# S6E2G3xH register map
Vendor: Spansion; File version: 2.0
CPU: CM4 r0p1, little endian, MPU, FPU, 4 interrupt priority bits
Registers are 32-bit, read-write, reset 0x0 unless marked. A register's access mark holds for its fields unless they carry their own. Offsets are from the block's base; [hi:lo] are bit positions; {n}, {i} and the like mark numbered series.

## USB0 — USB0 Function
Base 0x40042100
Same registers: USB1 0x40052100
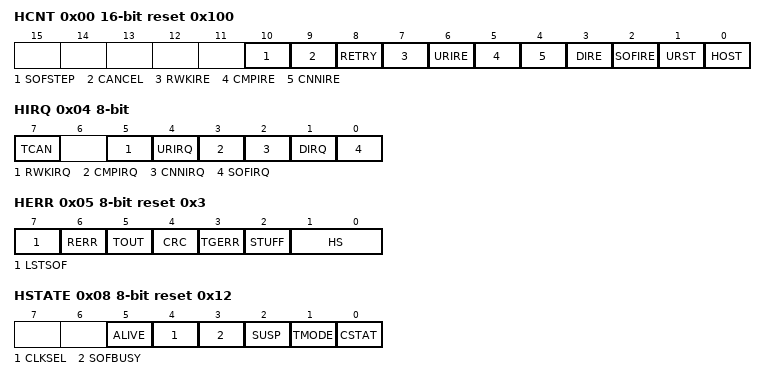
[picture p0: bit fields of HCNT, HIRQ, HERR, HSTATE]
0x00 HCNT 16-bit reset 0x100 — Host Control Register
  [10] SOFSTEP — SOF interrupt occurrence selection bit
  [9] CANCEL — token cancellation enable bit
  [8] RETRY — retry enable bit
  [7] RWKIRE — resume interrupt enable bit
  [6] URIRE — bus reset interrupt enable bit
  [5] CMPIRE — token completion interrupt enable bit
  [4] CNNIRE — device connection detection interrupt enable bit
  [3] DIRE — device disconnection detection interrupt enable bit
  [2] SOFIRE — SOF interrupt enable bit
  [1] URST — bus reset bit
  [0] HOST — host mode bit
0x04 HIRQ 8-bit — Host Interrupt Register
  [7] TCAN — token cancellation flag
  [5] RWKIRQ — remote Wake-up end flag
  [4] URIRQ — bus reset end flag
  [3] CMPIRQ — token completion flag
  [2] CNNIRQ — device connection detection flag
  [1] DIRQ — device disconnection detection flag
  [0] SOFIRQ — SOF starting flag
0x05 HERR 8-bit reset 0x3 — Host Error Status Register
  [7] LSTSOF — lost SOF flag
  [6] RERR — receive error flag
  [5] TOUT — timeout flag
  [4] CRC — CRC error flag
  [3] TGERR — toggle error flag
  [2] STUFF — stuffing error flag
  [1:0] HS — handshake status flags
0x08 HSTATE 8-bit reset 0x12 — Host Status Register
  [5] ALIVE — specify the keep-alive function in the low-speed mode
  [4] CLKSEL — USB operation clock selection bit
  [3] SOFBUSY — SOF busy flag
  [2] SUSP — suspend setting bit
  [1] TMODE ro — transmission mode flag
  [0] CSTAT ro — connection status flag
0x09 HFCOMP 8-bit — SOF Interrupt Frame Compare Register
  [7:0] FRAMECOMP — frame compare data
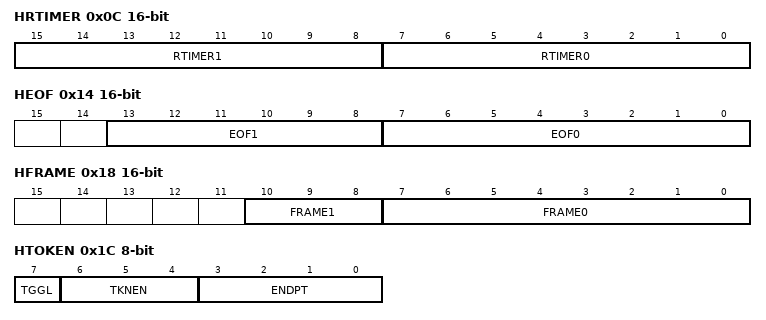
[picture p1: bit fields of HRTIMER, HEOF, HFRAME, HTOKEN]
0x0C HRTIMER 16-bit — Retry Timer Setup Register
  [15:8] RTIMER1 — retry timer setting 1
  [7:0] RTIMER0 — retry timer setting 0
0x10 HRTIMER2 8-bit — Retry Timer Setup Register 2
  [1:0] RTIMER2 — retry timer setting 2
0x11 HADR 8-bit — Host Address Register
  [6:0] ADDRESS — Host Address
0x14 HEOF 16-bit — EOF Setup Register
  [13:8] EOF1 — End Frame 1
  [7:0] EOF0 — End Frame 0
0x18 HFRAME 16-bit — Frame Setup Register
  [10:8] FRAME1 — Frame Setup 1
  [7:0] FRAME0 — Frame Setup 0
0x1C HTOKEN 8-bit — Host Token Endpoint Register
  [7] TGGL — toggle bit
  [6:4] TKNEN — token enable bits
  [3:0] ENDPT — endpoint bits
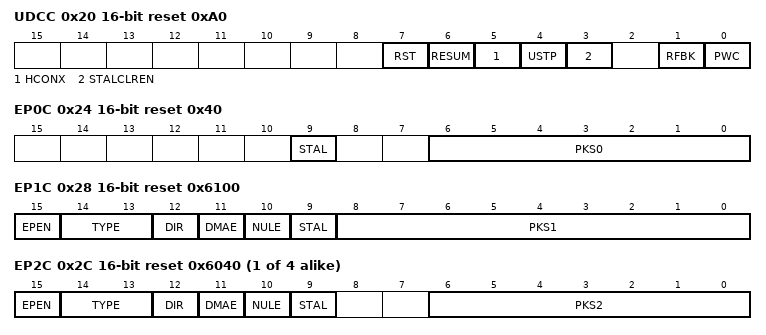
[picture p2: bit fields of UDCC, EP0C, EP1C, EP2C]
0x20 UDCC 16-bit reset 0xA0 — UDC Control Register
  [7] RST — Function Reset bit
  [6] RESUM — Resume Setting bit
  [5] HCONX — Host Connection bit
  [4] USTP — USB Operating Clock Stop bit
  [3] STALCLREN — Endpoint 1 to 5 STAL bit Clear Select bit
  [1] RFBK — Data Toggle Mode Select bit
  [0] PWC — Power Control bit
0x24 EP0C 16-bit reset 0x40 — EP0 Control Register
  [9] STAL — Endpoint 0 Stall Setting bit
  [6:0] PKS0 — Packet Size Endpoint 0 Setting bits
0x28 EP1C 16-bit reset 0x6100 — EP1 Control Register
  [15] EPEN — Endpoint Enable bit
  [14:13] TYPE — Endpoint Transfer Type Select bits
  [12] DIR — Endpoint Transfer Direction Select bit
  [11] DMAE — DMA Automatic Transfer Enable bit
  [10] NULE — Null Automatic Transfer Enable bit
  [9] STAL — Endpoint Stall Setting bit
  [8:0] PKS1 — Packet Size Setting bits
{0x24+4i} EP{i}C 16-bit reset 0x6040 (i=2..5) — EP{i} Control Register
  [15] EPEN — Endpoint Enable bit
  [14:13] TYPE — Endpoint Transfer Type Select bits
  [12] DIR — Endpoint Transfer Direction Select bit
  [11] DMAE — DMA Automatic Transfer Enable bit
  [10] NULE — Null Automatic Transfer Enable bit
  [9] STAL — Endpoint Stall Setting bit
  [6:0] PKS{i} — Packet Size Setting bits
0x3C TMSP 16-bit ro — Time Stamp Register
  [10:0] TMSP — Time Stamp bits
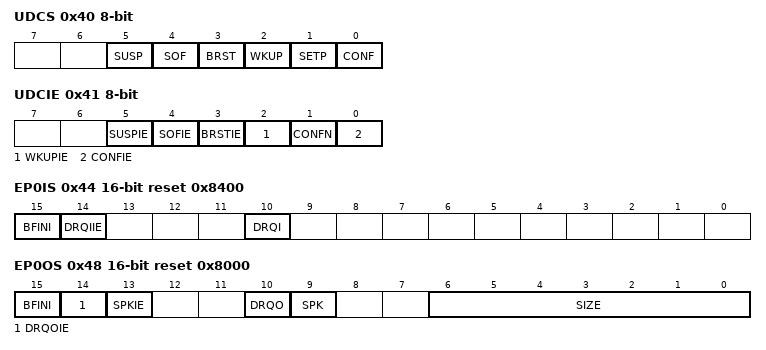
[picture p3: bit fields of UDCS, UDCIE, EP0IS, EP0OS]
0x40 UDCS 8-bit — UDC Status Register
  [5] SUSP — Suspend detection bit
  [4] SOF — SOF Detection bit
  [3] BRST — Bus Reset Detection bit
  [2] WKUP — Wake-up Detection bit
  [1] SETP — Setup Stage Detection bit
  [0] CONF — Configuration Detection bit
0x41 UDCIE 8-bit — UDC Interrupt Enable Register
  [5] SUSPIE — Suspend Interrupt Enable bit
  [4] SOFIE — SOF Reception Interrupt Enable bit
  [3] BRSTIE — Bus Reset Enable bit
  [2] WKUPIE — Wake-up Interrupt Enable bit
  [1] CONFN ro — Configuration Number Indication bit
  [0] CONFIE — Configuration Interrupt Enable bit
0x44 EP0IS 16-bit reset 0x8400 — EP0I Status Register
  [15] BFINI — Send Buffer Initialization bit
  [14] DRQIIE — Send Data Interrupt Enable bit
  [10] DRQI — Send/Receive Data Interrupt Request bit
0x48 EP0OS 16-bit reset 0x8000 — EP0O Status Register
  [15] BFINI — Receive Buffer Initialization bit
  [14] DRQOIE — Receive Data Interrupt Enable bit
  [13] SPKIE — Short Packet Interrupt Enable bit
  [10] DRQO — Receive Data Interrupt Request bit
  [9] SPK — Short Packet Interrupt Request bit
  [6:0] SIZE ro — Packet Size Indication bit
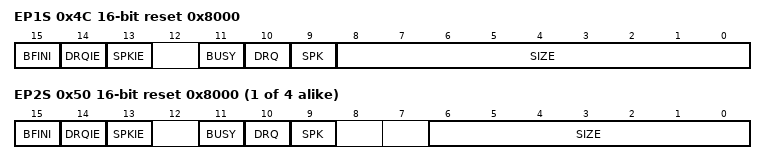
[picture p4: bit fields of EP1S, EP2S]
0x4C EP1S 16-bit reset 0x8000 — EP1 Status Register
  [15] BFINI — Send/Receive Buffer Initialization bit
  [14] DRQIE — Packet Transfer Interrupt Enable bit
  [13] SPKIE — Short Packet Interrupt Enable bit
  [11] BUSY ro — Busy Flag bit
  [10] DRQ — Packet Transfer Interrupt Request bit
  [9] SPK — Short Packet Interrupt Request bit
  [8:0] SIZE ro — packet SIZE
{0x48+4i} EP{i}S 16-bit reset 0x8000 (i=2..5) — EP{i} Status Register
  [15] BFINI — Send/Receive Buffer Initialization bit
  [14] DRQIE — Packet Transfer Interrupt Enable bit
  [13] SPKIE — Short Packet Interrupt Enable bit
  [11] BUSY ro — Busy Flag bit
  [10] DRQ — Packet Transfer Interrupt Request bit
  [9] SPK — Short Packet Interrupt Request bit
  [6:0] SIZE ro — packet SIZE
{0x60+4i} EP{i}DT 16-bit reset not defined (i=0..5) — EP{i} Data Register
  [15:0] BFDT — Endpoint Send/Receive Buffer Data

## Notices in the file
Copyright (C) 2015 Spansion LLC. All Rights Reserved.
This software is owned and published by:
Spansion LLC, 915 DeGuigne Dr. Sunnyvale, CA  94088-3453 ("Spansion").
BY DOWNLOADING, INSTALLING OR USING THIS SOFTWARE, YOU AGREE TO BE BOUND
BY ALL THE TERMS AND CONDITIONS OF THIS AGREEMENT.
This software contains source code for use with Spansion
components. This software is licensed by Spansion to be adapted only
for use in systems utilizing Spansion components. Spansion shall not be
responsible for misuse or illegal use of this software for devices not
supported herein.  Spansion is providing this software "AS IS" and will
not be responsible for issues arising from incorrect user implementation
of the software.
SPANSION MAKES NO WARRANTY, EXPRESS OR IMPLIED, ARISING BY LAW OR OTHERWISE,
REGARDING THE SOFTWARE (INCLUDING ANY ACOOMPANYING WRITTEN MATERIALS),
ITS PERFORMANCE OR SUITABILITY FOR YOUR INTENDED USE, INCLUDING,
WITHOUT LIMITATION, THE IMPLIED WARRANTY OF MERCHANTABILITY, THE IMPLIED
WARRANTY OF FITNESS FOR A PARTICULAR PURPOSE OR USE, AND THE IMPLIED
WARRANTY OF NONINFRINGEMENT.
SPANSION SHALL HAVE NO LIABILITY (WHETHER IN CONTRACT, WARRANTY, TORT,
NEGLIGENCE OR OTHERWISE) FOR ANY DAMAGES WHATSOEVER (INCLUDING, WITHOUT
LIMITATION, DAMAGES FOR LOSS OF BUSINESS PROFITS, BUSINESS INTERRUPTION,
LOSS OF BUSINESS INFORMATION, OR OTHER PECUNIARY LOSS) ARISING FROM USE OR
INABILITY TO USE THE SOFTWARE, INCLUDING, WITHOUT LIMITATION, ANY DIRECT,
INDIRECT, INCIDENTAL, SPECIAL OR CONSEQUENTIAL DAMAGES OR LOSS OF DATA,
SAVINGS OR PROFITS,
EVEN IF SPANSION HAS BEEN ADVISED OF THE POSSIBILITY OF SUCH DAMAGES.
YOU ASSUME ALL RESPONSIBILITIES FOR SELECTION OF THE SOFTWARE TO ACHIEVE YOUR
INTENDED RESULTS, AND FOR THE INSTALLATION OF, USE OF, AND RESULTS OBTAINED
FROM, THE SOFTWARE.
This software may be replicated in part or whole for the licensed use,
with the restriction that this Disclaimer and Copyright notice must be
included with each copy of this software, whether used in part or whole,
at all times.
